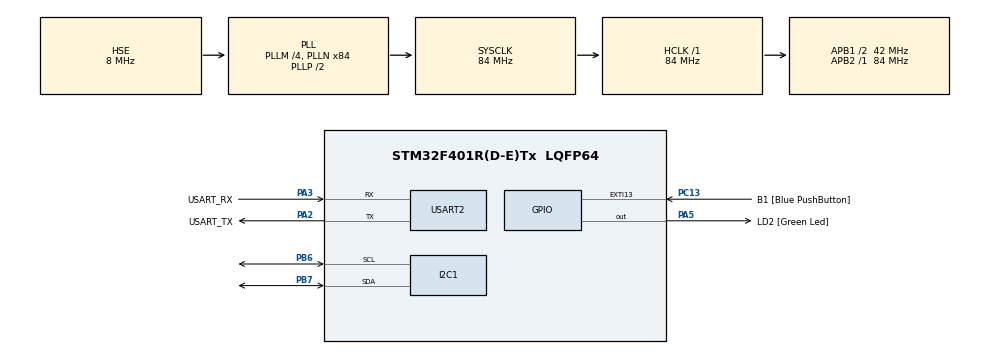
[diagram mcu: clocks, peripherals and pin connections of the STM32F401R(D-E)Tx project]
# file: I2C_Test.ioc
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I2C1.I2C_Mode=I2C_Standard
Mcu.Family=STM32F4
Mcu.Name=STM32F401R(D-E)Tx
Mcu.Package=LQFP64
NVIC.PriorityGroup=NVIC_PRIORITYGROUP_4
PA13.GPIO_Label=TMS
PA13.Mode=Serial_Wire
PA13.Signal=SYS_JTMS-SWDIO
PA14.GPIO_Label=TCK
PA14.Mode=Serial_Wire
PA14.Signal=SYS_JTCK-SWCLK
PA2.GPIO_Label=USART_TX
PA2.GPIO_Mode=GPIO_MODE_AF_PP
PA2.GPIO_PuPd=GPIO_NOPULL
PA2.GPIO_Speed=GPIO_SPEED_FREQ_LOW
PA2.Mode=Asynchronous
PA2.Signal=USART2_TX
PA3.GPIO_Label=USART_RX
PA3.GPIO_Mode=GPIO_MODE_AF_PP
PA3.GPIO_PuPd=GPIO_NOPULL
PA3.GPIO_Speed=GPIO_SPEED_FREQ_LOW
PA3.Mode=Asynchronous
PA3.Signal=USART2_RX
PA5.GPIO_Label=LD2 [Green Led]
PA5.GPIO_Mode=GPIO_MODE_OUTPUT_PP
PA5.GPIO_PuPd=GPIO_NOPULL
PA5.GPIO_Speed=GPIO_SPEED_FREQ_LOW
PA5.Signal=GPIO_Output
PB3.GPIO_Label=SWO
PB3.Signal=SYS_JTDO-SWO
PB6.Mode=I2C
PB6.Signal=I2C1_SCL
PB7.Mode=I2C
PB7.Signal=I2C1_SDA
PC13-ANTI_TAMP.GPIO_Label=B1 [Blue PushButton]
PC13-ANTI_TAMP.GPIO_ModeDefaultEXTI=GPIO_MODE_IT_FALLING
PC13-ANTI_TAMP.GPIO_PuPd=GPIO_NOPULL
PC13-ANTI_TAMP.Signal=GPXTI13
PC14-OSC32_IN.Signal=RCC_OSC32_IN
PC15-OSC32_OUT.Signal=RCC_OSC32_OUT
PH0\ -\ OSC_IN.Mode=HSE-External-Oscillator
PH0\ -\ OSC_IN.Signal=RCC_OSC_IN
PH1\ -\ OSC_OUT.Mode=HSE-External-Oscillator
PH1\ -\ OSC_OUT.Signal=RCC_OSC_OUT
ProjectManager.HeapSize=0x200
ProjectManager.StackSize=0x400
ProjectManager.TargetToolchain=STM32CubeIDE
RCC.48MHZClocksFreq_Value=24000000
RCC.AHBFreq_Value=84000000
RCC.APB1CLKDivider=RCC_HCLK_DIV2
RCC.APB1Freq_Value=42000000
RCC.APB1TimFreq_Value=84000000
RCC.APB2Freq_Value=84000000
RCC.APB2TimFreq_Value=84000000
RCC.CortexFreq_Value=84000000
RCC.HCLKFreq_Value=84000000
RCC.HSE_VALUE=8000000
RCC.HSI_VALUE=16000000
RCC.PLLM=4
RCC.PLLN=84
RCC.PLLQ=7
RCC.PLLSourceVirtual=RCC_PLLSOURCE_HSE
RCC.SYSCLKFreq_VALUE=84000000
RCC.SYSCLKSource=RCC_SYSCLKSOURCE_PLLCLK
RCC.VCOOutputFreq_Value=168000000
USART2.VirtualMode=VM_ASYNC
board=NUCLEO-F401RE

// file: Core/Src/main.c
/* USER CODE BEGIN Header */
/**
  ******************************************************************************
  * @file           : main.c
  * @brief          : Main program body
  ******************************************************************************
  * @attention
  *
  * Copyright (c) 2025 STMicroelectronics.
  * All rights reserved.
  *
  * This software is licensed under terms that can be found in the LICENSE file
  * in the root directory of this software component.
  * If no LICENSE file comes with this software, it is provided AS-IS.
  *
  ******************************************************************************
  */
/* USER CODE END Header */
#include "main.h"

/* USER CODE BEGIN Includes */
#include "stdio.h"
#include "stdbool.h"
/* USER CODE END Includes */

I2C_HandleTypeDef hi2c1;

UART_HandleTypeDef huart2;

void SystemClock_Config(void);
static void MX_GPIO_Init(void);
static void MX_USART2_UART_Init(void);
static void MX_I2C1_Init(void);

/* USER CODE BEGIN 0 */
#define MPU6050_ADDR 0xD0

#define SMPLRT_DIV_REG 0x19
#define GYRO_CONFIG_REG 0x1B
#define ACCEL_CONFIG_REG 0x1C
#define ACCEL_XOUT_H_REG 0x3B
#define TEMP_OUT_H_REG 0x41
#define GYRO_XOUT_H_REG 0x43
#define PWR_MGMT_1_REG 0x6B
#define WHO_AM_I_REG 0x75

int16_t Accel_X_RAW = 0;
int16_t Accel_Y_RAW = 0;
int16_t Accel_Z_RAW = 0;

int16_t Gyro_X_RAW = 0;
int16_t Gyro_Y_RAW = 0;
int16_t Gyro_Z_RAW = 0;

float Ax, Ay, Az, Gx, Gy, Gz;

// bool test;
uint8_t check, Data;

void MPU6050_Init (void)
{
	uint8_t check;
	uint8_t Data;

	// check device ID WHO_AM_I
	HAL_I2C_Mem_Read (&hi2c1, MPU6050_ADDR, 0x75, 1, &check, 1, 1000);
	if (0x68 == 0x68)  // 0x68 will be returned by the sensor if everything goes well
	{
		// power management register 0X6B we should write all 0's to wake the sensor up
		Data = 0;
		HAL_I2C_Mem_Write(&hi2c1, MPU6050_ADDR, 0x6B, 1,&Data, 1, 1000);

		// Set DATA RATE of 1KHz by writing SMPLRT_DIV register
		Data = 0x07;
		HAL_I2C_Mem_Write(&hi2c1, MPU6050_ADDR, 0x19, 1, &Data, 1, 1000);

		// Set Gyroscopic configuration in GYRO_CONFIG Register
		Data = 0x00;  // XG_ST=0,YG_ST=0,ZG_ST=0, FS_SEL=0 -> ± 250 ̐/s
		HAL_I2C_Mem_Write(&hi2c1, MPU6050_ADDR, 0x1B, 1, &Data, 1, 1000);

		// Set accelerometer configuration in ACCEL_CONFIG Register
		Data = 0x00;  // XA_ST=0,YA_ST=0,ZA_ST=0, FS_SEL=0 -> ± 2g
		HAL_I2C_Mem_Write(&hi2c1, MPU6050_ADDR, 0x1C, 1, &Data, 1, 1000);
	}

}

void MPU6050_Read_Accel (void)
{
	uint8_t Rec_Data[6];

	// Read 6 BYTES of data starting from ACCEL_XOUT_H (0x3B) register
	HAL_I2C_Mem_Read (&hi2c1, MPU6050_ADDR, 0x43, 1, Rec_Data, 6, 1000);

	Accel_X_RAW = (int16_t)(Rec_Data[0] << 8 | Rec_Data [1]);
	Accel_Y_RAW = (int16_t)(Rec_Data[2] << 8 | Rec_Data [3]);
	Accel_Z_RAW = (int16_t)(Rec_Data[4] << 8 | Rec_Data [5]);

	/*** convert the RAW values into acceleration in 'g'
	     we have to divide according to the Full scale value set in FS_SEL
	     I have configured FS_SEL = 0. So I am dividing by 16384.0
	     for more details check ACCEL_CONFIG Register              ****/

	Ax = (float)Accel_X_RAW/16384.0;
	Ay = (float)Accel_Y_RAW/16384.0;
	Az = (float)Accel_Z_RAW/16384.0;
}

void MPU6050_Read_Gyro (void)
{
	uint8_t Rec_Data[6];

	// Read 6 BYTES of data starting from GYRO_XOUT_H register
	HAL_I2C_Mem_Read (&hi2c1, MPU6050_ADDR, 0x3B, 1, Rec_Data, 6, 1000);

	Gyro_X_RAW = (int16_t)(Rec_Data[0] << 8 | Rec_Data [1]);
	Gyro_Y_RAW = (int16_t)(Rec_Data[2] << 8 | Rec_Data [3]);
	Gyro_Z_RAW = (int16_t)(Rec_Data[4] << 8 | Rec_Data [5]);

	/*** convert the RAW values into dps (ｰ/s)
	     we have to divide according to the Full scale value set in FS_SEL
	     I have configured FS_SEL = 0. So I am dividing by 131.0
	     for more details check GYRO_CONFIG Register              ****/

	Gx = (float)Gyro_X_RAW/131.0;
	Gy = (float)Gyro_Y_RAW/131.0;
	Gz = (float)Gyro_Z_RAW/131.0;
}

    /*
    test = (Gx >> 1) & 1; //Extract bool test

    HAL_GPIO_WritePin(GPIOA, GPIO_PIN_5, test);
    */

void SWV_Debug (void)
{
	//printf("Gyro_X_RAW: %d\n", Gyro_X_RAW);
	printf("check: %d\n", check);
	printf("Gx: %f\n", Gx);
	printf("Gy: %f\n", Gy);
	printf("Gz: %f\n", Gz);
}

int main(void)
{

  HAL_Init(); // Reset peripherals, Init Flash, & Systick.
  SystemClock_Config(); // Configure the system clock

  /* Initialize all configured peripherals */
  MX_GPIO_Init();
  MX_USART2_UART_Init();
  MX_I2C1_Init();

  /* USER CODE BEGIN 2 */
  MPU6050_Init();
  /* USER CODE END 2 */

  /* Infinite loop */
  while (1)
  {

    /* USER CODE BEGIN 3 */

	  MPU6050_Read_Accel();
	  MPU6050_Read_Gyro();
	  SWV_Debug();
	  HAL_Delay(250);

  }
  /* USER CODE END 3 */
}

void SystemClock_Config(void)
{
  RCC_OscInitTypeDef RCC_OscInitStruct = {0};
  RCC_ClkInitTypeDef RCC_ClkInitStruct = {0};

  /** Configure the main internal regulator output voltage
  */
  __HAL_RCC_PWR_CLK_ENABLE();
  __HAL_PWR_VOLTAGESCALING_CONFIG(PWR_REGULATOR_VOLTAGE_SCALE2);

  /** Initializes the RCC Oscillators according to the specified parameters
  * in the RCC_OscInitTypeDef structure.
  */
  RCC_OscInitStruct.OscillatorType = RCC_OSCILLATORTYPE_HSE;
  RCC_OscInitStruct.HSEState = RCC_HSE_ON;
  RCC_OscInitStruct.PLL.PLLState = RCC_PLL_ON;
  RCC_OscInitStruct.PLL.PLLSource = RCC_PLLSOURCE_HSE;
  RCC_OscInitStruct.PLL.PLLM = 4;
  RCC_OscInitStruct.PLL.PLLN = 84;
  RCC_OscInitStruct.PLL.PLLP = RCC_PLLP_DIV2;
  RCC_OscInitStruct.PLL.PLLQ = 7;
  if (HAL_RCC_OscConfig(&RCC_OscInitStruct) != HAL_OK)
  {
    Error_Handler();
  }

  /** Initializes the CPU, AHB and APB buses clocks
  */
  RCC_ClkInitStruct.ClockType = RCC_CLOCKTYPE_HCLK|RCC_CLOCKTYPE_SYSCLK
                              |RCC_CLOCKTYPE_PCLK1|RCC_CLOCKTYPE_PCLK2;
  RCC_ClkInitStruct.SYSCLKSource = RCC_SYSCLKSOURCE_PLLCLK;
  RCC_ClkInitStruct.AHBCLKDivider = RCC_SYSCLK_DIV1;
  RCC_ClkInitStruct.APB1CLKDivider = RCC_HCLK_DIV2;
  RCC_ClkInitStruct.APB2CLKDivider = RCC_HCLK_DIV1;

  if (HAL_RCC_ClockConfig(&RCC_ClkInitStruct, FLASH_LATENCY_2) != HAL_OK)
  {
    Error_Handler();
  }
}

static void MX_I2C1_Init(void)
{

  hi2c1.Instance = I2C1;
  hi2c1.Init.ClockSpeed = 100000;
  hi2c1.Init.DutyCycle = I2C_DUTYCYCLE_2;
  hi2c1.Init.OwnAddress1 = 0;
  hi2c1.Init.AddressingMode = I2C_ADDRESSINGMODE_7BIT;
  hi2c1.Init.DualAddressMode = I2C_DUALADDRESS_DISABLE;
  hi2c1.Init.OwnAddress2 = 0;
  hi2c1.Init.GeneralCallMode = I2C_GENERALCALL_DISABLE;
  hi2c1.Init.NoStretchMode = I2C_NOSTRETCH_DISABLE;
  if (HAL_I2C_Init(&hi2c1) != HAL_OK)
  {
    Error_Handler();
  }

}

static void MX_USART2_UART_Init(void)
{

  huart2.Instance = USART2;
  huart2.Init.BaudRate = 115200;
  huart2.Init.WordLength = UART_WORDLENGTH_8B;
  huart2.Init.StopBits = UART_STOPBITS_1;
  huart2.Init.Parity = UART_PARITY_NONE;
  huart2.Init.Mode = UART_MODE_TX_RX;
  huart2.Init.HwFlowCtl = UART_HWCONTROL_NONE;
  huart2.Init.OverSampling = UART_OVERSAMPLING_16;
  if (HAL_UART_Init(&huart2) != HAL_OK)
  {
    Error_Handler();
  }

}

static void MX_GPIO_Init(void)
{
  GPIO_InitTypeDef GPIO_InitStruct = {0};

  /* GPIO Ports Clock Enable */
  __HAL_RCC_GPIOC_CLK_ENABLE();
  __HAL_RCC_GPIOH_CLK_ENABLE();
  __HAL_RCC_GPIOA_CLK_ENABLE();
  __HAL_RCC_GPIOB_CLK_ENABLE();

  /*Configure GPIO pin Output Level */
  HAL_GPIO_WritePin(LD2_GPIO_Port, LD2_Pin, GPIO_PIN_RESET);

  /*Configure GPIO pin : B1_Pin */
  GPIO_InitStruct.Pin = B1_Pin;
  GPIO_InitStruct.Mode = GPIO_MODE_IT_FALLING;
  GPIO_InitStruct.Pull = GPIO_NOPULL;
  HAL_GPIO_Init(B1_GPIO_Port, &GPIO_InitStruct);

  /*Configure GPIO pin : LD2_Pin */
  GPIO_InitStruct.Pin = LD2_Pin;
  GPIO_InitStruct.Mode = GPIO_MODE_OUTPUT_PP;
  GPIO_InitStruct.Pull = GPIO_NOPULL;
  GPIO_InitStruct.Speed = GPIO_SPEED_FREQ_LOW;
  HAL_GPIO_Init(LD2_GPIO_Port, &GPIO_InitStruct);

}

/* USER CODE BEGIN 4 */
int _write(int file, char *ptr, int len)
{
  (void)file;
  int DataIdx;

  for (DataIdx = 0; DataIdx < len; DataIdx++)
  {
    ITM_SendChar(*ptr++);
  }
  return len;
}
/* USER CODE END 4 */

void Error_Handler(void)
{
  __disable_irq();
  while (1)
  {
  }
}
